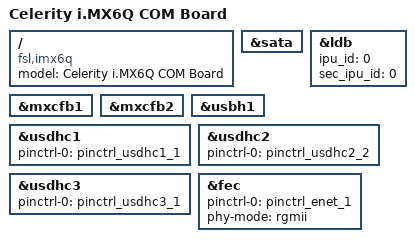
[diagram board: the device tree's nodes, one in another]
/*
 * Copyright 2013 Freescale Semiconductor, Inc.
 *
 * Author: Fabio Estevam <fabio.estevam@freescale.com>
 *
 * This program is free software; you can redistribute it and/or modify
 * it under the terms of the GNU General Public License version 2 as
 * published by the Free Software Foundation.
 *
 */
/dts-v1/;
#include "imx6q.dtsi"
#include "imx6qdl-celerityCOM.dtsi"

/ {
	model = "Celerity i.MX6Q COM Board";
	compatible = "fsl,imx6q";
};

&sata {
	status = "okay";
};

&ldb {
	ipu_id = <0>;
	sec_ipu_id = <0>;
};

&mxcfb1 {
	status = "okay";
};

&mxcfb2 {
	status = "okay";
};

&usbh1 {
	status = "okay";
};


&usdhc1 {
	pinctrl-names = "default";
	pinctrl-0 = <&pinctrl_usdhc1_1>;
	status = "okay";
};

&usdhc2 {
	pinctrl-names = "default";
	pinctrl-0 = <&pinctrl_usdhc2_2>;
	status = "okay";
};

&usdhc3 {
	pinctrl-names = "default";
	pinctrl-0 = <&pinctrl_usdhc3_1>;
	status = "okay";
};

&fec {
	pinctrl-names = "default";
	pinctrl-0 = <&pinctrl_enet_1>;
	phy-mode = "rgmii";
	status = "okay";
};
